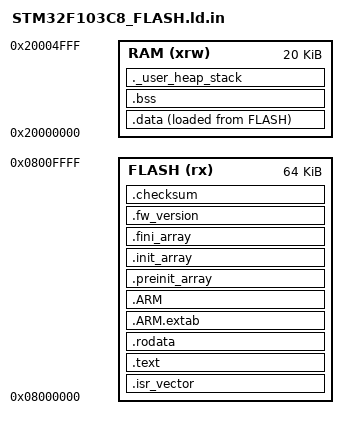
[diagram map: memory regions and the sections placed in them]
/* Test-local F103C8 layout based on the generated stm32-cmake linker script. */
ENTRY(Reset_Handler)

_estack = 0x20000000 + 20K;
_Min_Heap_Size = @HEAP_SIZE@;
_Min_Stack_Size = @STACK_SIZE@;

MEMORY
{
    FLASH (rx)      : ORIGIN = 0x8000000, LENGTH = 64K
    RAM (xrw)      : ORIGIN = 0x20000000, LENGTH = 20K


}

SECTIONS
{
  .isr_vector :
  {
    . = ALIGN(4);
    __checksum_start = .;
    KEEP(*(.isr_vector))
    /* Materialize padding before the 16-byte-aligned FreeRTOS port text. */
    . = ALIGN(16);
  } >FLASH

  .text :
  {
    . = ALIGN(4);
    *(.text)
    *(.text*)
    *(.glue_7)
    *(.glue_7t)
    *(.eh_frame)

    KEEP (*(.init))
    KEEP (*(.fini))

    . = ALIGN(4);
    _etext = .;
  } >FLASH

  .rodata :
  {
    . = ALIGN(4);
    *(.rodata)
    *(.rodata*)
    . = ALIGN(4);
  } >FLASH

  .ARM.extab   : { *(.ARM.extab* .gnu.linkonce.armextab.*) } >FLASH
  .ARM : {
    __exidx_start = .;
    *(.ARM.exidx*)
    __exidx_end = .;
  } >FLASH

  .preinit_array     :
  {
    PROVIDE_HIDDEN (__preinit_array_start = .);
    KEEP (*(.preinit_array*))
    PROVIDE_HIDDEN (__preinit_array_end = .);
  } >FLASH
  .init_array :
  {
    PROVIDE_HIDDEN (__init_array_start = .);
    KEEP (*(SORT(.init_array.*)))
    KEEP (*(.init_array*))
    PROVIDE_HIDDEN (__init_array_end = .);
  } >FLASH
  .fini_array :
  {
    PROVIDE_HIDDEN (__fini_array_start = .);
    KEEP (*(SORT(.fini_array.*)))
    KEEP (*(.fini_array*))
    PROVIDE_HIDDEN (__fini_array_end = .);
  } >FLASH

  _sidata = LOADADDR(.data);

  .data :
  {
    . = ALIGN(4);
    _sdata = .;
    *(.data)
    *(.data*)

    . = ALIGN(4);
    _edata = .;
  } >RAM AT> FLASH

  /* All FLASH load data, including .data, precedes the checksum. */
  .fw_version :
  {
    . = ALIGN(4);
    __fw_version_start = .;
    KEEP(*(.fw_version))
    . = ALIGN(4);
  } >FLASH
  .checksum :
  {
    . = ALIGN(4);
    __checksum_end = .;
    LONG(0);
  } >FLASH
  __checksum_size = __checksum_end - __checksum_start;

  . = ALIGN(4);
  .bss :
  {
    _sbss = .;
    __bss_start__ = _sbss;
    *(.bss)
    *(.bss*)
    *(COMMON)

    . = ALIGN(4);
    _ebss = .;
    __bss_end__ = _ebss;
  } >RAM

  ._user_heap_stack :
  {
    . = ALIGN(8);
    PROVIDE ( end = . );
    PROVIDE ( _end = . );
    . = . + _Min_Heap_Size;
    . = . + _Min_Stack_Size;
    . = ALIGN(8);
  } >RAM

  /DISCARD/ :
  {
    libc.a ( * )
    libm.a ( * )
    libgcc.a ( * )
  }

  .ARM.attributes 0 : { *(.ARM.attributes) }

}
